VERSION ""

NS_ :

BS_:

BU_: XXX

BO_ 151 STEERING: 8 XXX
 SG_ STEERING : 7|16@0+ (1,-32643) [0|65535] "" XXX

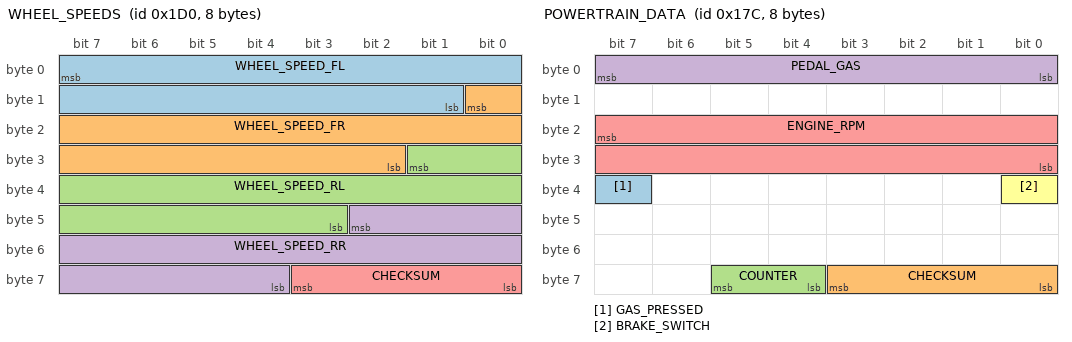
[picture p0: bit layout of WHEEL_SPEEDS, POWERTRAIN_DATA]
BO_ 464 WHEEL_SPEEDS: 8 XXX
 SG_ WHEEL_SPEED_FL : 7|15@0+ (0.01,0) [0|250] "kph" XXX
 SG_ WHEEL_SPEED_FR : 8|15@0+ (0.01,0) [0|250] "kph" XXX
 SG_ WHEEL_SPEED_RL : 25|15@0+ (0.01,0) [0|250] "kph" XXX
 SG_ WHEEL_SPEED_RR : 42|15@0+ (0.01,0) [0|250] "kph" XXX
 SG_ CHECKSUM : 59|4@0+ (1,0) [0|3] "" XXX

BO_ 380 POWERTRAIN_DATA: 8 XXX
 SG_ GAS_PRESSED : 39|1@0+ (1,0) [0|1] "" XXX
 SG_ CHECKSUM : 59|4@0+ (1,0) [0|15] "" XXX
 SG_ COUNTER : 61|2@0+ (1,0) [0|3] "" XXX
 SG_ PEDAL_GAS : 7|8@0+ (1,0) [0|255] "" XXX
 SG_ ENGINE_RPM : 23|16@0+ (1,0) [0|15000] "rpm" XXX
 SG_ BRAKE_SWITCH : 32|1@0+ (1,0) [0|1] "" XXX

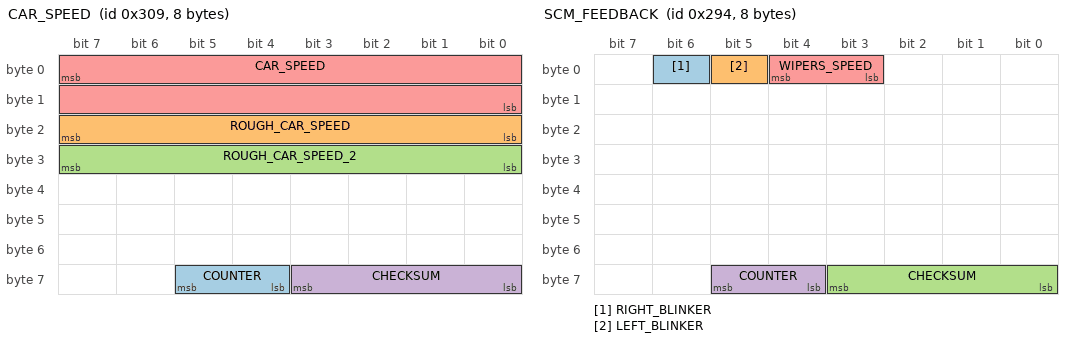
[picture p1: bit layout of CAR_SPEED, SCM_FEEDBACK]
BO_ 777 CAR_SPEED: 8 XXX
 SG_ COUNTER : 61|2@0+ (1,0) [0|3] "" XXX
 SG_ ROUGH_CAR_SPEED : 23|8@0+ (1.60934,0) [0|255] "kph" XXX
 SG_ ROUGH_CAR_SPEED_2 : 31|8@0+ (1.60934,0) [0|255] "kph" XXX
 SG_ CHECKSUM : 59|4@0+ (1,0) [0|17] "" XXX
 SG_ CAR_SPEED : 7|16@0+ (0.01,0) [0|255] "kph" XXX

BO_ 344 ENGINE_DATA: 8 XXX
 SG_ XMISSION_SPEED2 : 39|16@0+ (0.01,0) [0|250] "kph" XXX
 SG_ XMISSION_SPEED : 7|16@0+ (0.01,0) [0|250] "kph" XXX

BO_ 660 SCM_FEEDBACK: 8 XXX
 SG_ RIGHT_BLINKER : 6|1@0+ (1,0) [0|1] "" XXX
 SG_ LEFT_BLINKER : 5|1@0+ (1,0) [0|1] "" XXX
 SG_ CHECKSUM : 59|4@0+ (1,0) [0|15] "" XXX
 SG_ COUNTER : 61|2@0+ (1,0) [0|3] "" XXX
 SG_ WIPERS_SPEED : 4|2@0+ (1,0) [0|3] "" XXX

BO_ 356 STALK_STATUS: 8 XXX
 SG_ HEADLIGHTS : 0|2@1+ (1,0) [0|3] "" XXX

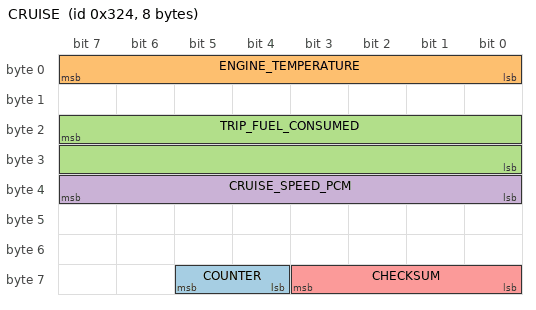
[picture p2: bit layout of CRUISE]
BO_ 804 CRUISE: 8 XXX
 SG_ COUNTER : 61|2@0+ (1,0) [0|3] "" XXX
 SG_ ENGINE_TEMPERATURE : 7|8@0+ (1,0) [0|255] "" XXX
 SG_ TRIP_FUEL_CONSUMED : 23|16@0+ (1,0) [0|65535] "" XXX
 SG_ CRUISE_SPEED_PCM : 39|8@0+ (1,0) [0|255] "kph" XXX
 SG_ CHECKSUM : 59|4@0+ (1,0) [0|15] "" XXX

BO_ 1029 untitled: 8 XXX

BO_ 545 XXX_221: 8 XXX
 SG_ ECON_ON : 23|1@0+ (1,0) [0|1] "" XXX
 SG_ SPORT_ON : 22|1@0+ (1,0) [0|1] "" XXX

BO_ 401 GEARBOX: 8 XXX
 SG_ GEAR_SHIFT : 2|1@0+ (1,0) [0|1] "" XXX
